# STM32U5xx register map
File version: 1.7
Registers are 32-bit, read-write, reset 0x0 unless marked. A register's access mark holds for its fields unless they carry their own. Offsets are from the block's base; [hi:lo] are bit positions; {n}, {i} and the like mark numbered series; 'fields as' and 'values as' point back to an identical list.

## LPGPIO1
Base 0x46020000
Same registers: SEC_LPGPIO1 0x56020000
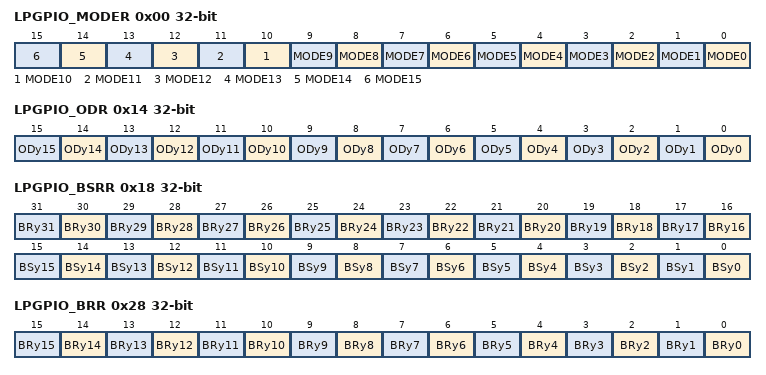
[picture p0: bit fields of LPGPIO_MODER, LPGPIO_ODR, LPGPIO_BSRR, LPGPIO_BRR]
0x00 LPGPIO_MODER — LPGPIO port mode register
  [n] MODE{n} (n=0..15)
0x10 LPGPIO_IDR ro — LPGPIO port input data register
  [15:0] IDy
0x14 LPGPIO_ODR — LPGPIO port output data register
  [n] ODy{n} (n=0..15)
0x18 LPGPIO_BSRR wo — LPGPIO port bit set/reset register
  [n] BRy{n} (n=16..31), [n] BSy{n} (n=0..15)
0x28 LPGPIO_BRR ro — LPGPIO port bit reset register
  [n] BRy{n} (n=0..15)

## OCTOSPIM — OCTOSPI I/O manager
Base 0x420C4000
Same registers: SEC_OCTOSPIM 0x520C4000
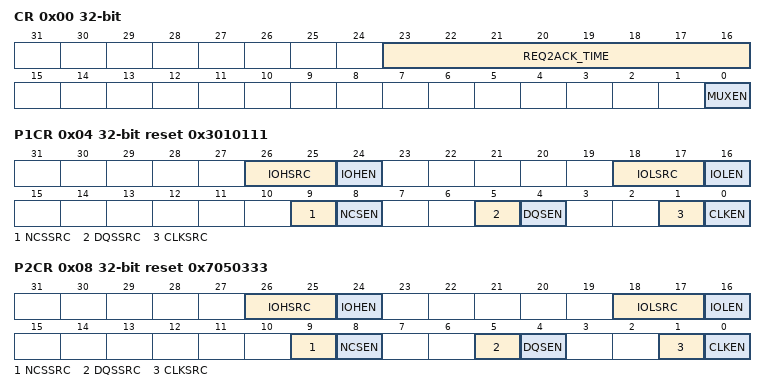
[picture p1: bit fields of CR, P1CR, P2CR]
0x00 CR — control register
  [23:16] REQ2ACK_TIME — REQ to ACK time
  [0] MUXEN — Multiplexed mode enable
0x04 P1CR reset 0x3010111 — OCTOSPI I/O manager Port 1 configuration register
  [26:25] IOHSRC — IOHSR
  [24] IOHEN
  [18:17] IOLSRC
  [16] IOLEN
  [9] NCSSRC
  [8] NCSEN
  [5] DQSSRC
  [4] DQSEN
  [1] CLKSRC
  [0] CLKEN
0x08 P2CR reset 0x7050333 — OCTOSPI I/O manager Port 2 configuration register
  fields as P1CR

## ADC4
Base 0x46021000
Same registers: SEC_ADC4 0x56021000
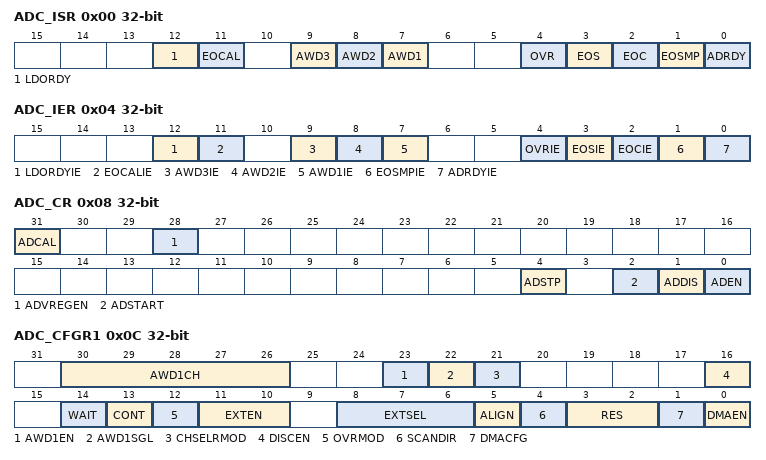
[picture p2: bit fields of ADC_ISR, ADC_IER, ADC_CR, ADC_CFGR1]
0x00 ADC_ISR — ADC interrupt and status register
  [12] LDORDY, [11] EOCAL, [9] AWD3, [8] AWD2, [7] AWD1, [4] OVR, [3] EOS, [2] EOC, [1] EOSMP, [0] ADRDY
0x04 ADC_IER — ADC interrupt enable register
  [12] LDORDYIE, [11] EOCALIE, [9] AWD3IE, [8] AWD2IE, [7] AWD1IE, [4] OVRIE, [3] EOSIE, [2] EOCIE, [1] EOSMPIE, [0] ADRDYIE
0x08 ADC_CR access per field — ADC control register
  [31] ADCAL ro, [28] ADVREGEN rw, [4] ADSTP ro, [2] ADSTART ro, [1] ADDIS ro, [0] ADEN ro
0x0C ADC_CFGR1 — ADC configuration register
  [30:26] AWD1CH, [23] AWD1EN, [22] AWD1SGL, [21] CHSELRMOD, [16] DISCEN, [14] WAIT, [13] CONT, [12] OVRMOD, [11:10] EXTEN, [8:6] EXTSEL, [5] ALIGN, [4] SCANDIR, [3:2] RES, [1] DMACFG, [0] DMAEN
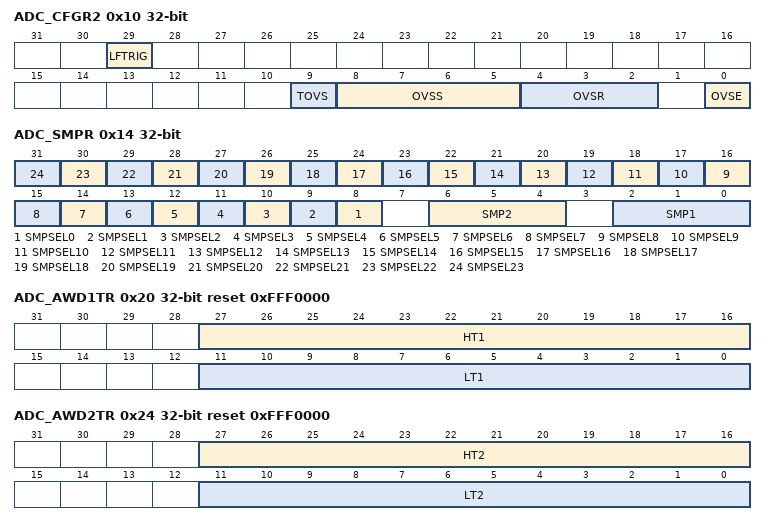
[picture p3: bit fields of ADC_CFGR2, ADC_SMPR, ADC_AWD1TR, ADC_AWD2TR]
0x10 ADC_CFGR2 — ADC configuration register 2
  [29] LFTRIG, [9] TOVS, [8:5] OVSS, [4:2] OVSR, [0] OVSE
0x14 ADC_SMPR — ADC sample time register
  [n+8] SMPSEL{n} (n=0..23), [6:4] SMP2, [2:0] SMP1
0x20 ADC_AWD1TR reset 0xFFF0000 — ADC watchdog threshold register
  [27:16] HT1, [11:0] LT1
0x24 ADC_AWD2TR reset 0xFFF0000 — ADC watchdog threshold register
  [27:16] HT2, [11:0] LT2
0x28 ADC_CHSELRMOD0 — ADC channel selection register [alternate]
  [23:0] CHSEL
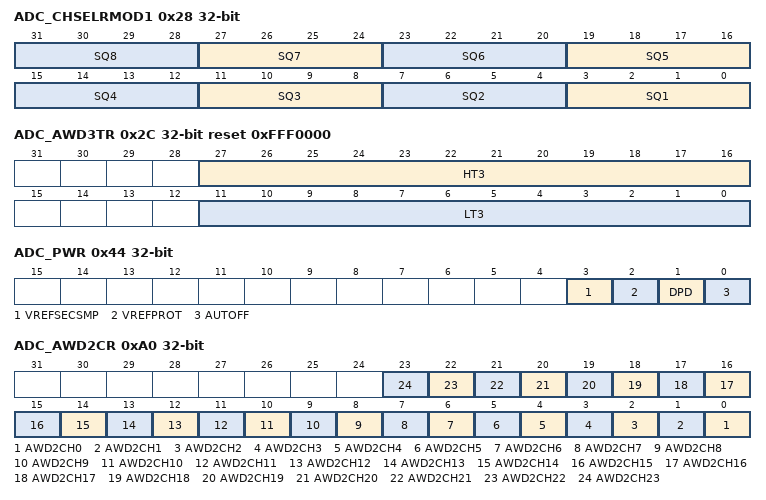
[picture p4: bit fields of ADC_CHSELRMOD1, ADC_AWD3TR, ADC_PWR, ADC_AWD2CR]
0x28 ADC_CHSELRMOD1 (alternate view of ADC_CHSELRMOD0) — ADC channel selection register [alternate]
  [4n-1:4n-4] SQ{n} (n=1..8)
0x2C ADC_AWD3TR reset 0xFFF0000 — ADC watchdog threshold register
  [27:16] HT3, [11:0] LT3
0x40 ADC_DR ro — ADC data register
  [15:0] DATA
0x44 ADC_PWR — ADC data register
  [3] VREFSECSMP, [2] VREFPROT, [1] DPD, [0] AUTOFF
0xA0 ADC_AWD2CR — ADC Analog Watchdog 2 Configuration register
  [n] AWD2CH{n} (n=0..23)
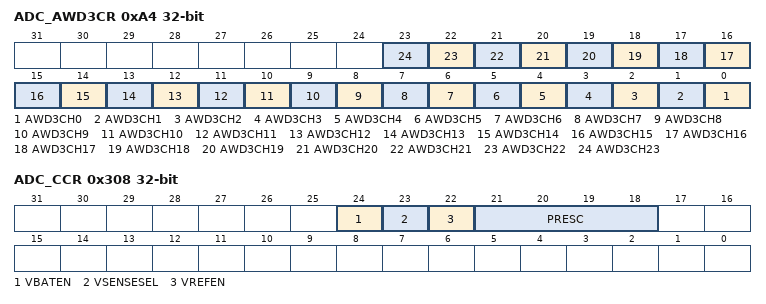
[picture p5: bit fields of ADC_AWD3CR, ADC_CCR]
0xA4 ADC_AWD3CR — ADC Analog Watchdog 3 Configuration register
  [n] AWD3CH{n} (n=0..23)
0xC4 ADC_CALFACT — ADC Calibration factor
  [6:0] CALFACT
0xD0 ADC_OR — ADC option register
  [0] CHN21SEL
0x308 ADC_CCR — ADC common configuration register
  [24] VBATEN, [23] VSENSESEL, [22] VREFEN, [21:18] PRESC

## RNG — Random number generator
Base 0x420C0800
Same registers: SEC_RNG 0x520C0800
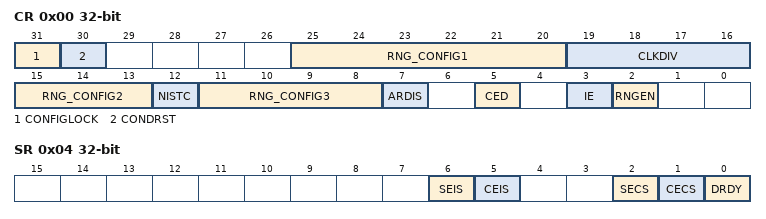
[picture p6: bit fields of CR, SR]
0x00 CR — control register
  [31] CONFIGLOCK — RNG Config Lock
  [30] CONDRST — Conditioning soft reset
  [25:20] RNG_CONFIG1 — RNG configuration 1
  [19:16] CLKDIV — Clock divider factor
  [15:13] RNG_CONFIG2 — RNG configuration 2
  [12] NISTC — Non NIST compliant
  [11:8] RNG_CONFIG3 — RNG configuration 3
  [7] ARDIS — Auto reset disable
  [5] CED — Clock error detection
  [3] IE — Interrupt Enable
  [2] RNGEN — True random number generator enable
0x04 SR access per field — status register
  [6] SEIS rw — Seed error interrupt status
  [5] CEIS rw — Clock error interrupt status
  [2] SECS ro — Seed error current status
  [1] CECS ro — Clock error current status
  [0] DRDY ro — Data ready
0x08 DR ro — data register
  [31:0] RNDATA — Random data
0x10 HTCR reset 0x6274 — health test control register
  [31:0] HTCFG — health test configuration

## Notices in the file
Copyright (c) 2021 STMicroelectronics.
SPDX-License-Identifier: Apache-2.0
Licensed under the Apache License, Version 2.0 (the "License");
you may not use this file except in compliance with the License.
You may obtain a copy of the License at
http://www.apache.org/licenses/LICENSE-2.0
Unless required by applicable law or agreed to in writing, software
distributed under the License is distributed on an "AS IS" BASIS,
WITHOUT WARRANTIES OR CONDITIONS OF ANY KIND, either express or implied.
See the License for the specific language governing permissions and
limitations under the License.
